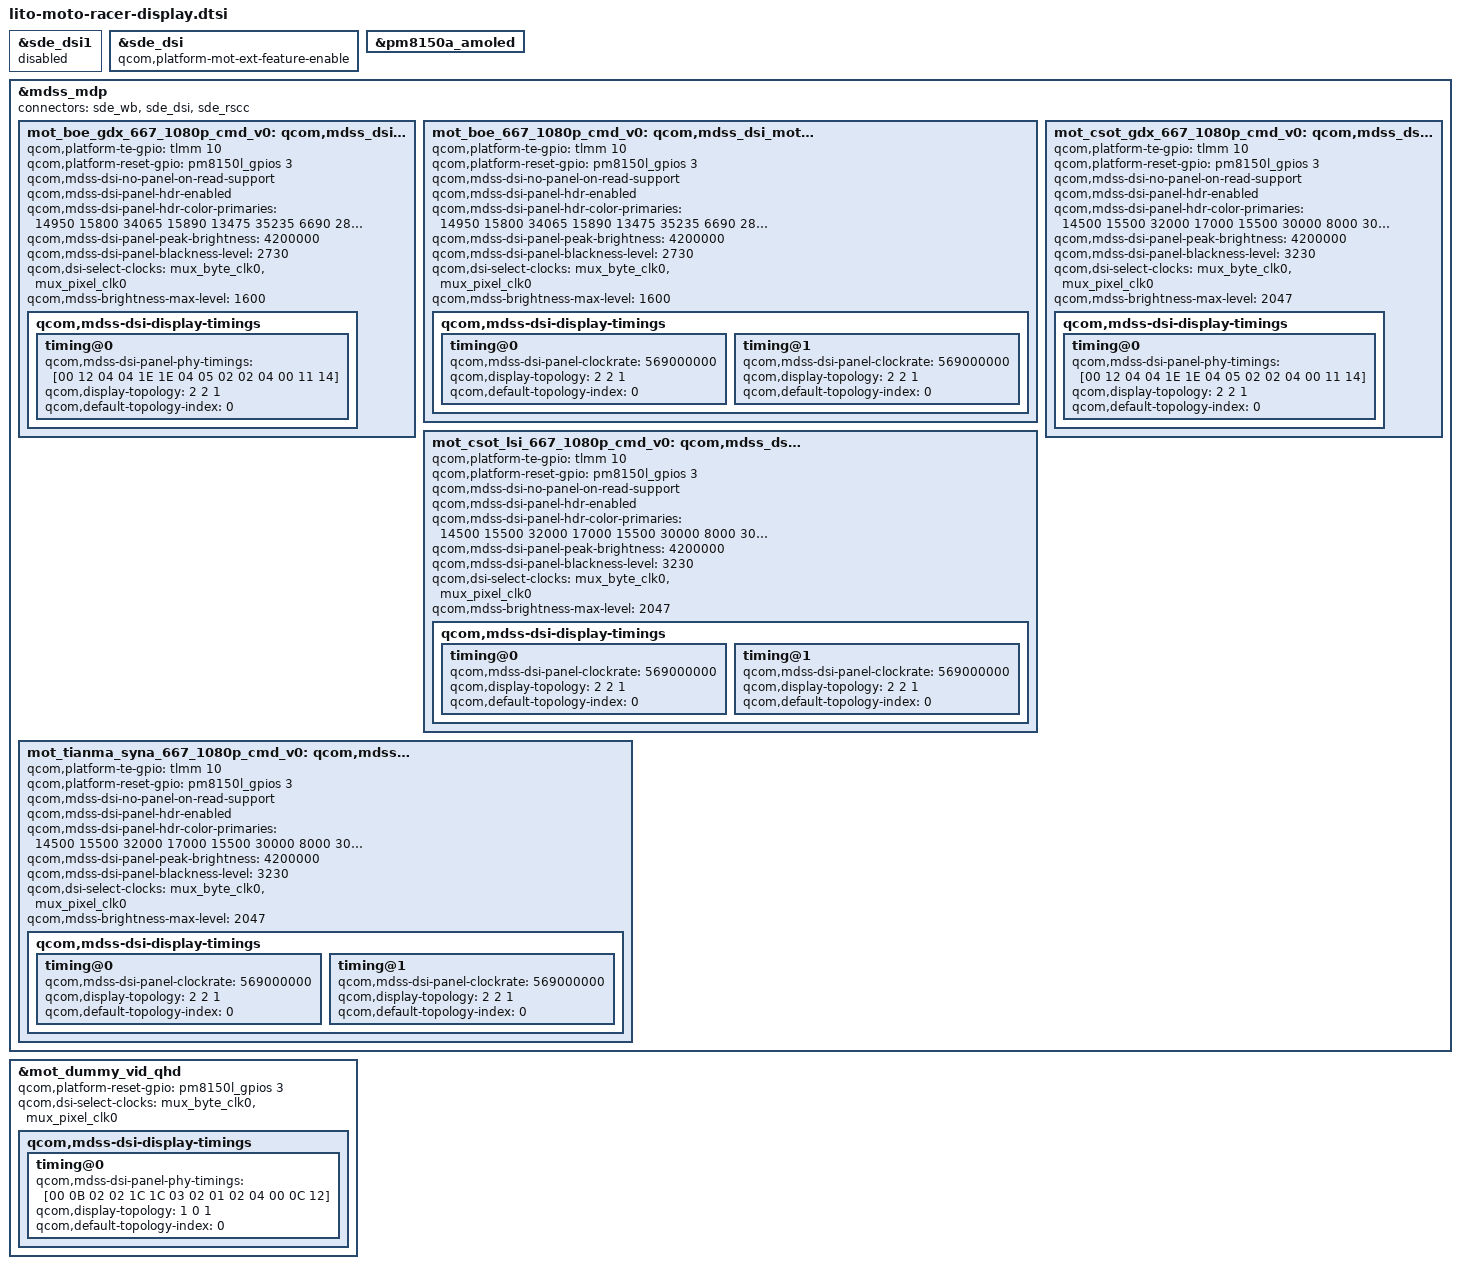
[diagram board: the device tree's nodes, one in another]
/* Copyright (c) 2019, The Linux Foundation. All rights reserved.
 *
 * This program is free software; you can redistribute it and/or modify
 * it under the terms of the GNU General Public License version 2 and
 * only version 2 as published by the Free Software Foundation.
 *
 * This program is distributed in the hope that it will be useful,
 * but WITHOUT ANY WARRANTY; without even the implied warranty of
 * MERCHANTABILITY or FITNESS FOR A PARTICULAR PURPOSE.  See the
 * GNU General Public License for more details.
 */

#include <dt-bindings/clock/mdss-7nm-pll-clk.h>
#include "lito-sde-display.dtsi"
#include "dsi-panel-mot-dummy-qhd-video.dtsi"

&sde_dsi1 {
	status = "disabled";
};

&sde_dsi {
        qcom,platform-mot-ext-feature-enable;
};

&pm8150a_amoled {
	status = "ok";
};


&mdss_mdp {
	connectors = <&sde_wb &sde_dsi &sde_rscc>;

	mot_boe_gdx_667_1080p_cmd_v0: qcom,mdss_dsi_mot_boe_gdx_667_1080p_cmd_v0 {
		#include "dsi-panel-mot-boe-gdx-667-1080p-racer-cmd-common.dtsi"
	};

	mot_boe_667_1080p_cmd_v0: qcom,mdss_dsi_mot_boe_667_1080p_cmd_v0 {
		#include "dsi-panel-mot-boe-667-1080p-racer-cmd-common.dtsi"
	};

	mot_csot_gdx_667_1080p_cmd_v0: qcom,mdss_dsi_mot_csot_gdx_667_1080p_cmd_v0 {
		#include "dsi-panel-mot-csot-gdx-667-1080p-racer-cmd-common.dtsi"
	};

	mot_csot_lsi_667_1080p_cmd_v0: qcom,mdss_dsi_mot_csot_lsi_667_1080p_cmd_v0 {
		#include "dsi-panel-mot-csot-667-1080p-racer-cmd-common.dtsi"
	};

	mot_tianma_syna_667_1080p_cmd_v0: qcom,mdss_dsi_mot_tianma_syna_667_1080p_cmd_v0 {
		#include "dsi-panel-mot-tianma-667-1080p-racer-cmd-common.dtsi"
	};

};


&mot_boe_667_1080p_cmd_v0 {
	qcom,platform-te-gpio = <&tlmm 10 0>;
	qcom,platform-reset-gpio = <&pm8150l_gpios 3 0>;
	//qcom,panel-supply-entries = <&dsi_panel_pwr_supply>;
	qcom,mdss-dsi-no-panel-on-read-support;

	qcom,mdss-dsi-panel-hdr-enabled;
	qcom,mdss-dsi-panel-hdr-color-primaries = <14950 15800 34065
		15890 13475 35235 6690 2885>;
	qcom,mdss-dsi-panel-peak-brightness = <4200000>;
	qcom,mdss-dsi-panel-blackness-level = <2730>;
	qcom,dsi-select-clocks = "mux_byte_clk0", "mux_pixel_clk0";
	qcom,mdss-brightness-max-level = <1600>;
	qcom,mdss-dsi-display-timings {
		timing@0 {
			qcom,mdss-dsi-panel-clockrate = <569000000>;
			qcom,display-topology = <2 2 1>;
			qcom,default-topology-index = <0>;
		};
		timing@1 {
			qcom,mdss-dsi-panel-clockrate = <569000000>;
			qcom,display-topology = <2 2 1>;
			qcom,default-topology-index = <0>;
		};
	};
};

&mot_boe_gdx_667_1080p_cmd_v0 {
	qcom,platform-te-gpio = <&tlmm 10 0>;
	qcom,platform-reset-gpio = <&pm8150l_gpios 3 0>;
	//qcom,panel-supply-entries = <&dsi_panel_pwr_supply>;
	qcom,mdss-dsi-no-panel-on-read-support;

	qcom,mdss-dsi-panel-hdr-enabled;
	qcom,mdss-dsi-panel-hdr-color-primaries = <14950 15800 34065
		15890 13475 35235 6690 2885>;
	qcom,mdss-dsi-panel-peak-brightness = <4200000>;
	qcom,mdss-dsi-panel-blackness-level = <2730>;
	qcom,dsi-select-clocks = "mux_byte_clk0", "mux_pixel_clk0";
	qcom,mdss-brightness-max-level = <1600>;
	qcom,mdss-dsi-display-timings {
		timing@0 {
			/* Phy 4; w=2880 h=2340; 10bits 90hz; 3.75x dsc */
			qcom,mdss-dsi-panel-phy-timings = [00 12 04 04 1E 1E 04
							05 02 02 04 00 11 14];
			qcom,display-topology = <2 2 1>;
			qcom,default-topology-index = <0>;
		};
	};
};

&mot_csot_gdx_667_1080p_cmd_v0 {
	qcom,platform-te-gpio = <&tlmm 10 0>;
	qcom,platform-reset-gpio = <&pm8150l_gpios 3 0>;
	//qcom,panel-supply-entries = <&dsi_panel_pwr_supply>;
	qcom,mdss-dsi-no-panel-on-read-support;

	qcom,mdss-dsi-panel-hdr-enabled;
	qcom,mdss-dsi-panel-hdr-color-primaries = <14500 15500 32000
	        17000 15500 30000 8000 3000>;
	qcom,mdss-dsi-panel-peak-brightness = <4200000>;
	qcom,mdss-dsi-panel-blackness-level = <3230>;
	qcom,dsi-select-clocks = "mux_byte_clk0", "mux_pixel_clk0";
	qcom,mdss-brightness-max-level = <2047>;
	qcom,mdss-dsi-display-timings {
		timing@0 {
			/* Phy 4; w=2880 h=2340; 10bits 90hz; 3.75x dsc */
			qcom,mdss-dsi-panel-phy-timings = [00 12 04 04 1E 1E 04
							05 02 02 04 00 11 14];
			qcom,display-topology = <2 2 1>;
			qcom,default-topology-index = <0>;
		};
	};
};

&mot_csot_lsi_667_1080p_cmd_v0 {
	qcom,platform-te-gpio = <&tlmm 10 0>;
	qcom,platform-reset-gpio = <&pm8150l_gpios 3 0>;
	//qcom,panel-supply-entries = <&dsi_panel_pwr_supply>;
	qcom,mdss-dsi-no-panel-on-read-support;

	qcom,mdss-dsi-panel-hdr-enabled;
	qcom,mdss-dsi-panel-hdr-color-primaries = <14500 15500 32000
	        17000 15500 30000 8000 3000>;
	qcom,mdss-dsi-panel-peak-brightness = <4200000>;
	qcom,mdss-dsi-panel-blackness-level = <3230>;
	qcom,dsi-select-clocks = "mux_byte_clk0", "mux_pixel_clk0";
	qcom,mdss-brightness-max-level = <2047>;
	qcom,mdss-dsi-display-timings {
		timing@0 {
			qcom,mdss-dsi-panel-clockrate = <569000000>;
			qcom,display-topology = <2 2 1>;
			qcom,default-topology-index = <0>;
		};
		timing@1 {
			qcom,mdss-dsi-panel-clockrate = <569000000>;
			qcom,display-topology = <2 2 1>;
			qcom,default-topology-index = <0>;
		};
	};
};

&mot_tianma_syna_667_1080p_cmd_v0 {
	qcom,platform-te-gpio = <&tlmm 10 0>;
	qcom,platform-reset-gpio = <&pm8150l_gpios 3 0>;
	//qcom,panel-supply-entries = <&dsi_panel_pwr_supply>;
	qcom,mdss-dsi-no-panel-on-read-support;

	qcom,mdss-dsi-panel-hdr-enabled;
	qcom,mdss-dsi-panel-hdr-color-primaries = <14500 15500 32000
	        17000 15500 30000 8000 3000>;
	qcom,mdss-dsi-panel-peak-brightness = <4200000>;
	qcom,mdss-dsi-panel-blackness-level = <3230>;
	qcom,dsi-select-clocks = "mux_byte_clk0", "mux_pixel_clk0";
	qcom,mdss-brightness-max-level = <2047>;
	qcom,mdss-dsi-display-timings {
		timing@0 {
			qcom,mdss-dsi-panel-clockrate = <569000000>;
			qcom,display-topology = <2 2 1>;
			qcom,default-topology-index = <0>;
		};
		timing@1 {
			qcom,mdss-dsi-panel-clockrate = <569000000>;
			qcom,display-topology = <2 2 1>;
			qcom,default-topology-index = <0>;
		};
	};
};


&mot_dummy_vid_qhd {
	qcom,platform-reset-gpio = <&pm8150l_gpios 3 0>;

	qcom,dsi-select-clocks = "mux_byte_clk0", "mux_pixel_clk0";
	qcom,mdss-dsi-display-timings {
		timing@0 {
			qcom,mdss-dsi-panel-phy-timings = [00 0B 02 02 1C 1C 03
							02 01 02 04 00 0C 12];
			qcom,display-topology = <1 0 1>;
			qcom,default-topology-index = <0>;
		};
	};
};
